# EDMA_TRIG_XBAR_EDMA_TRIG_XBAR register map
Vendor: Texas Instruments
Peripheral module from a debugger description file (folder AM263).
Registers are 32-bit, read-only, reset 0x66948100 unless marked. A register's access mark holds for its fields unless they carry their own. Offsets are as the file gives them; lines under a group give offsets from that group; [hi:lo] are bit positions; {n}, {i} and the like mark numbered series; 'fields as' and 'values as' point back to an identical list; <NAME> marks a mode.

## EDMA_TRIG_XBAR_EDMA_TRIG_XBAR
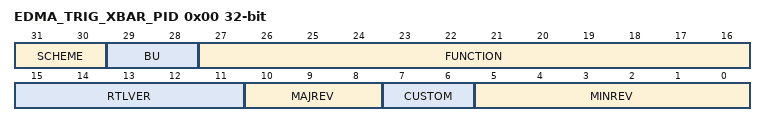
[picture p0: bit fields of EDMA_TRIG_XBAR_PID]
0x00 EDMA_TRIG_XBAR_PID
  [31:30] SCHEME
  [29:28] BU
  [27:16] FUNCTION
  [15:11] RTLVER — rtl version
  [10:8] MAJREV — major version
  [7:6] CUSTOM — custom id
  [5:0] MINREV — minor version
0x04 EDMA_TRIG_XBAR_MUXCNTL 16-bit rw reset 0x0
  [16] INT_ENABLE — interrupt output enable for interrupt N
  [7:0] ENABLE — Mux control for interrupt N
